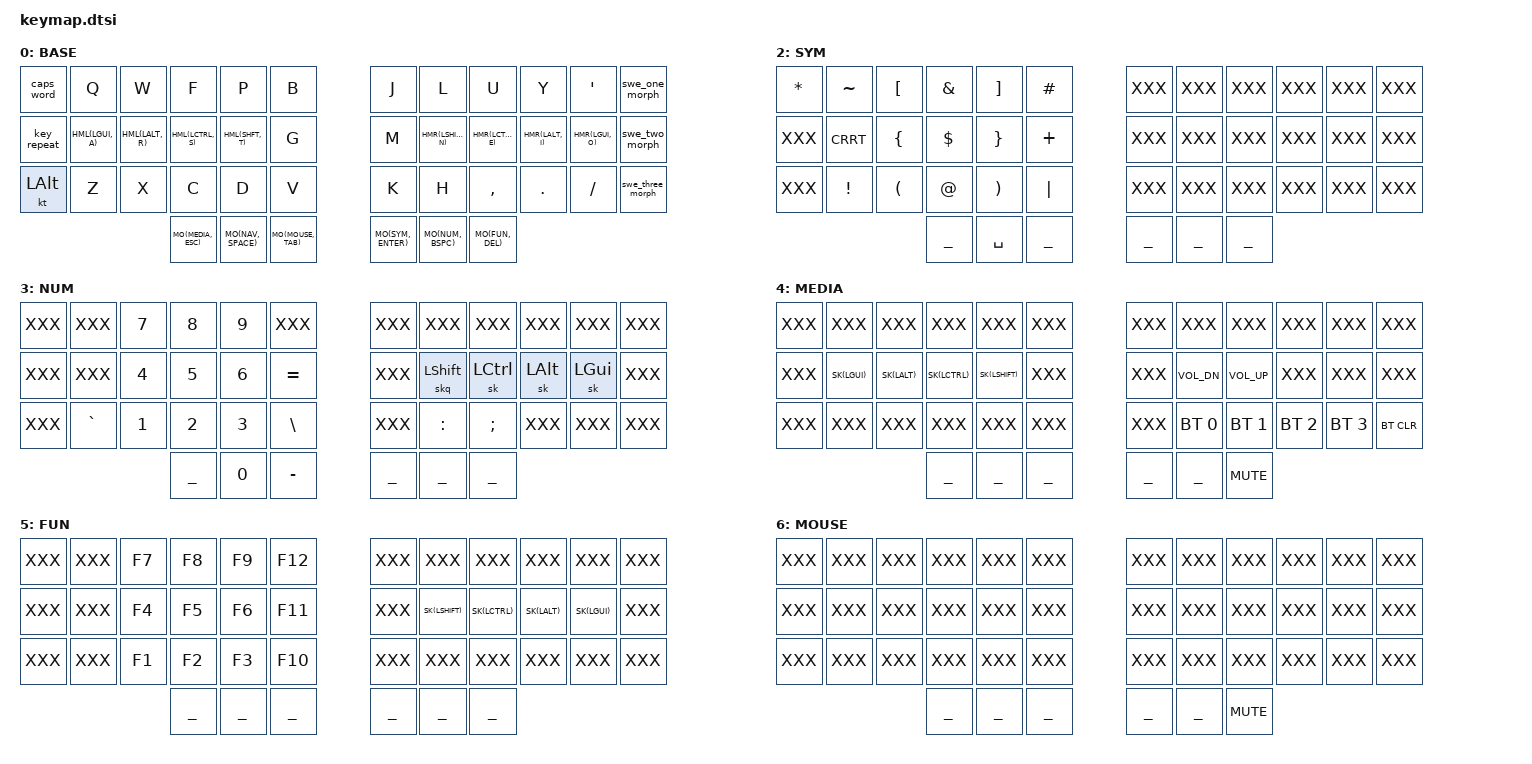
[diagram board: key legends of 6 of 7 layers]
compatible = "zmk,keymap";

base_layer {
  label = "BASE";
  bindings = <
    // ╭────────────────┬───────────────┬───────────────┬────────────────┬────────────────┬────────────────╮       ╭────────────────┬────────────────┬────────────────┬────────────────┬────────────────┬────────────────╮
           &caps_word        &kp Q            &kp W           &kp F            &kp P            &kp B                    &kp J            &kp L            &kp U            &kp Y           &kp SQT       &swe_one_morph 
    // ├────────────────┼───────────────┼───────────────┼────────────────┼────────────────┼────────────────┤       ├────────────────┼────────────────┼────────────────┼────────────────┼────────────────┼────────────────┤
           &key_repeat    HML(LGUI, A)    HML(LALT, R)     HML(LCTRL, S)     HML(SHFT, T)       &kp G                    &kp M        HMR(LSHIFT, N)    HMR(LCTRL, E)    HMR(LALT, I)     HMR(LGUI, O)    &swe_two_morph 
    // ├────────────────┼───────────────┼───────────────┼────────────────┼────────────────┼────────────────┤       ├────────────────┼────────────────┼────────────────┼────────────────┼────────────────┼────────────────┤
           &kt LALT          &kp Z            &kp X           &kp C            &kp D            &kp V                    &kp K            &kp H            &kp COMMA        &kp DOT         &kp SLASH     &swe_three_morph 
    // ╰────────────────┴───────────────┴───────────────┴────────────────┴────────────────┼────────────────┤       ├────────────────┼────────────────┼────────────────┴────────────────┴────────────────┴────────────────╯
                                                          MO(MEDIA, ESC)   MO(NAV, SPACE)   MO(MOUSE, TAB)           MO(SYM, ENTER)    MO(NUM, BSPC)    MO(FUN, DEL)
    //                                                  ╰────────────────┴────────────────┴────────────────╯       ╰────────────────┴────────────────┴────────────────╯
  >;
};

nav_layer {
  label = "NAV";
  bindings = <
    // ╭────────────────┬───────────────┬───────────────┬────────────────┬────────────────┬────────────────╮       ╭────────────────┬────────────────┬────────────────┬────────────────┬────────────────┬────────────────╮
              XXX         &kp LS(LC(W))  &kp LS(LC(LEFT)) &kp LS(LC(DOWN))  &kp LS(LC(UP))  &kp LS(LC(RIGHT))      &kp LG(LC(LA(LEFT))) &kp LC(TAB)   &kp LC(LS(TAB)) &kp LG(LC(LA(RIGHT)))  XXX              XXX
    // ├────────────────┼───────────────┼───────────────┼────────────────┼────────────────┼────────────────┤       ├────────────────┼────────────────┼────────────────┼────────────────┼────────────────┼────────────────┤
              XXX            &sk LGUI       &sk LALT        &sk LCTRL       &skq LSHIFT     &kp LC(KP_PLUS)            &kp LEFT         &kp DOWN          &kp UP           &kp RIGHT         XXX              XXX
    // ├────────────────┼───────────────┼───────────────┼────────────────┼────────────────┼────────────────┤       ├────────────────┼────────────────┼────────────────┼────────────────┼────────────────┼────────────────┤
              XXX             XXX              XXX     &kp LS(LA((PLUS))) &kp LS(LA((MINUS))) &kp LC(MINUS)               XXX           &kp PG_DN         &kp PG_UP        &kp END          &kp INS           XXX 
    // ╰────────────────┴───────────────┴───────────────┴────────────────┴────────────────┼────────────────┤       ├────────────────┼────────────────┼────────────────┴────────────────┴────────────────┴────────────────╯
                                                              ___               ___             ___                    &kp ENTER        &kp BSPC          &kp DEL
    //                                                  ╰────────────────┴────────────────┴────────────────╯       ╰────────────────┴────────────────┴────────────────╯
  >;
};

sym_layer {
  label = "SYM";
  bindings = <
    // ╭────────────────┬───────────────┬───────────────┬────────────────┬────────────────┬────────────────╮       ╭────────────────┬────────────────┬────────────────┬────────────────┬────────────────┬────────────────╮
           &kp ASTRK        &kp TILDE       &kp LBKT         &kp AMPS         &kp RBKT         &kp HASH                   XXX              XXX              XXX              XXX              XXX              XXX
    // ├────────────────┼───────────────┼───────────────┼────────────────┼────────────────┼────────────────┤       ├────────────────┼────────────────┼────────────────┼────────────────┼────────────────┼────────────────┤
              XXX           &kp CRRT        &kp LBRC         &kp DLLR         &kp RBRC         &kp PLUS                   XXX              XXX              XXX              XXX              XXX              XXX
    // ├────────────────┼───────────────┼───────────────┼────────────────┼────────────────┼────────────────┤       ├────────────────┼────────────────┼────────────────┼────────────────┼────────────────┼────────────────┤
              XXX           &kp EXCL        &kp LPAR         &kp AT           &kp RPAR         &kp PIPE                   XXX              XXX              XXX              XXX              XXX              XXX
    // ╰────────────────┴───────────────┴───────────────┴────────────────┴────────────────┼────────────────┤       ├────────────────┼────────────────┼────────────────┴────────────────┴────────────────┴────────────────╯
                                                               ___            &kp SPACE        &kp UNDER                  ___              ___              ___
    //                                                  ╰────────────────┴────────────────┴────────────────╯       ╰────────────────┴────────────────┴────────────────╯
  >;
};

num_layer {
  label = "NUM";
  bindings = <
    // ╭────────────────┬───────────────┬───────────────┬────────────────┬────────────────┬────────────────╮       ╭────────────────┬────────────────┬────────────────┬────────────────┬────────────────┬────────────────╮
              XXX             XXX           &kp NUM_7       &kp NUM_8        &kp NUM_9          XXX                      XXX              XXX              XXX              XXX              XXX              XXX
    // ├────────────────┼───────────────┼───────────────┼────────────────┼────────────────┼────────────────┤       ├────────────────┼────────────────┼────────────────┼────────────────┼────────────────┼────────────────┤
              XXX             XXX           &kp NUM_4       &kp NUM_5        &kp NUM_6        &kp EQL                    XXX            &skq LSHIFT      &sk LCTRL       &sk LALT         &sk LGUI         XXX  
    // ├────────────────┼───────────────┼───────────────┼────────────────┼────────────────┼────────────────┤       ├────────────────┼────────────────┼────────────────┼────────────────┼────────────────┼────────────────┤
              XXX           &kp GRAVE       &kp NUM_1       &kp NUM_2        &kp NUM_3        &kp BSLH                   XXX            &kp COLON         &kp SEMI          XXX              XXX              XXX
    // ╰────────────────┴───────────────┴───────────────┴────────────────┴────────────────┼────────────────┤       ├────────────────┼────────────────┼────────────────┴────────────────┴────────────────┴────────────────╯
                                                               ___           &kp NUM_0        &kp MINUS                  ___              ___              ___
    //                                                  ╰────────────────┴────────────────┴────────────────╯       ╰────────────────┴────────────────┴────────────────╯
  >;
};

media_layer {
  label = "MEDIA";
  bindings = <
    // ╭────────────────┬───────────────┬───────────────┬────────────────┬────────────────┬────────────────╮       ╭────────────────┬────────────────┬────────────────┬────────────────┬────────────────┬────────────────╮
              XXX             XXX             XXX             XXX              XXX              XXX                      XXX              XXX              XXX              XXX              XXX              XXX
    // ├────────────────┼───────────────┼───────────────┼────────────────┼────────────────┼────────────────┤       ├────────────────┼────────────────┼────────────────┼────────────────┼────────────────┼────────────────┤
              XXX           SK(LGUI)        SK(LALT)        SK(LCTRL)        SK(LSHIFT)         XXX                      XXX           &kp C_VOL_DN     &kp C_VOL_UP        XXX              XXX              XXX
    // ├────────────────┼───────────────┼───────────────┼────────────────┼────────────────┼────────────────┤       ├────────────────┼────────────────┼────────────────┼────────────────┼────────────────┼────────────────┤
              XXX             XXX             XXX             XXX              XXX              XXX                      XXX           &bt BT_SEL 0     &bt BT_SEL 1     &bt BT_SEL 2     &bt BT_SEL 3      &bt BT_CLR
    // ╰────────────────┴───────────────┴───────────────┴────────────────┴────────────────┼────────────────┤       ├────────────────┼────────────────┼────────────────┴────────────────┴────────────────┴────────────────╯
                                                              ___               ___             ___                      ___              ___            &kp C_MUTE
    //                                                  ╰────────────────┴────────────────┴────────────────╯       ╰────────────────┴────────────────┴────────────────╯
  >;
};

fun_layer {
  label = "FUN";
  bindings = <
    // ╭────────────────┬───────────────┬───────────────┬────────────────┬────────────────┬────────────────╮       ╭────────────────┬────────────────┬────────────────┬────────────────┬────────────────┬────────────────╮
              XXX             XXX             &kp F7          &kp F8          &kp F9            &kp F12                 XXX               XXX              XXX              XXX              XXX              XXX
    // ├────────────────┼───────────────┼───────────────┼────────────────┼────────────────┼────────────────┤       ├────────────────┼────────────────┼────────────────┼────────────────┼────────────────┼────────────────┤
              XXX             XXX             &kp F4          &kp F5          &kp F6            &kp F11                 XXX            SK(LSHIFT)        SK(LCTRL)        SK(LALT)          SK(LGUI)          XXX  
    // ├────────────────┼───────────────┼───────────────┼────────────────┼────────────────┼────────────────┤       ├────────────────┼────────────────┼────────────────┼────────────────┼────────────────┼────────────────┤
              XXX             XXX             &kp F1          &kp F2          &kp F3            &kp F10                 XXX               XXX              XXX              XXX              XXX              XXX 
    // ╰────────────────┴───────────────┴───────────────┴────────────────┴────────────────┼────────────────┤       ├────────────────┼────────────────┼────────────────┴────────────────┴────────────────┴────────────────╯
                                                               ___              ___             ___                      ___              ___              ___
    //                                                  ╰────────────────┴────────────────┴────────────────╯       ╰────────────────┴────────────────┴────────────────╯
  >;
};


MOUSE_layer {
  label = "MOUSE";
  bindings = <
    // ╭────────────────┬───────────────┬───────────────┬────────────────┬────────────────┬────────────────╮       ╭────────────────┬────────────────┬────────────────┬────────────────┬────────────────┬────────────────╮
              XXX             XXX             XXX             XXX              XXX              XXX                      XXX              XXX              XXX              XXX              XXX              XXX
    // ├────────────────┼───────────────┼───────────────┼────────────────┼────────────────┼────────────────┤       ├────────────────┼────────────────┼────────────────┼────────────────┼────────────────┼────────────────┤
              XXX             XXX             XXX             XXX              XXX              XXX                      XXX              XXX              XXX              XXX              XXX              XXX 
    // ├────────────────┼───────────────┼───────────────┼────────────────┼────────────────┼────────────────┤       ├────────────────┼────────────────┼────────────────┼────────────────┼────────────────┼────────────────┤
              XXX             XXX             XXX             XXX              XXX              XXX                      XXX              XXX              XXX              XXX              XXX              XXX 
    // ╰────────────────┴───────────────┴───────────────┴────────────────┴────────────────┼────────────────┤       ├────────────────┼────────────────┼────────────────┴────────────────┴────────────────┴────────────────╯
                                                              ___              ___              ___                      ___              ___            &kp C_MUTE
    //                                                  ╰────────────────┴────────────────┴────────────────╯       ╰────────────────┴────────────────┴────────────────╯
  >;
};

